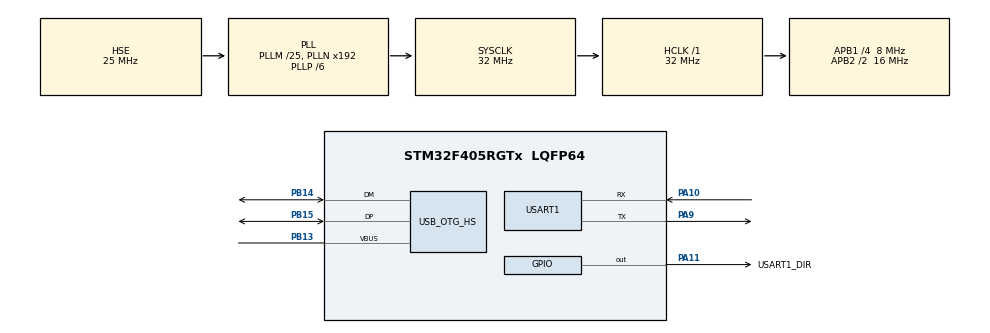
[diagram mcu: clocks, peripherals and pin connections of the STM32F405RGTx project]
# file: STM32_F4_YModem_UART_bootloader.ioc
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Mcu.Family=STM32F4
Mcu.Name=STM32F405RGTx
Mcu.Package=LQFP64
NVIC.OTG_HS_IRQn=true\:0\:0\:false\:false\:true\:false\:true
NVIC.PriorityGroup=NVIC_PRIORITYGROUP_4
PA10.Mode=Asynchronous
PA10.Signal=USART1_RX
PA11.GPIO_Label=USART1_DIR
PA11.Signal=GPIO_Output
PA13.Mode=Serial_Wire
PA13.Signal=SYS_JTMS-SWDIO
PA14.Mode=Serial_Wire
PA14.Signal=SYS_JTCK-SWCLK
PA9.Mode=Asynchronous
PA9.Signal=USART1_TX
PB13.Mode=Activate_VBUS_FS
PB13.Signal=USB_OTG_HS_VBUS
PB14.Mode=Device_Only_FS
PB14.Signal=USB_OTG_HS_DM
PB15.Mode=Device_Only_FS
PB15.Signal=USB_OTG_HS_DP
PH0-OSC_IN.Mode=HSE-External-Oscillator
PH0-OSC_IN.Signal=RCC_OSC_IN
PH1-OSC_OUT.Mode=HSE-External-Oscillator
PH1-OSC_OUT.Signal=RCC_OSC_OUT
ProjectManager.HeapSize=0x200
ProjectManager.StackSize=0x400
ProjectManager.TargetToolchain=STM32CubeIDE
RCC.48MHZClocksFreq_Value=48000000
RCC.AHBFreq_Value=32000000
RCC.APB1CLKDivider=RCC_HCLK_DIV4
RCC.APB1Freq_Value=8000000
RCC.APB1TimFreq_Value=16000000
RCC.APB2CLKDivider=RCC_HCLK_DIV2
RCC.APB2Freq_Value=16000000
RCC.APB2TimFreq_Value=32000000
RCC.CortexFreq_Value=32000000
RCC.HCLKFreq_Value=32000000
RCC.HSE_VALUE=25000000
RCC.HSI_VALUE=16000000
RCC.LSE_VALUE=32768
RCC.PLLM=25
RCC.PLLP=RCC_PLLP_DIV6
RCC.SYSCLKFreq_VALUE=32000000
RCC.SYSCLKSource=RCC_SYSCLKSOURCE_PLLCLK
RCC.VCOOutputFreq_Value=192000000
USART1.VirtualMode=VM_ASYNC
USB_DEVICE.CLASS_NAME_HS=CDC
USB_DEVICE.MANUFACTURER_STRING-CDC_HS=Micronix
USB_DEVICE.PRODUCT_STRING_CDC_HS=Micronix VD Device
USB_DEVICE.VirtualMode-CDC_HS=Cdc
USB_DEVICE.VirtualModeHS=Cdc_HS
USB_OTG_HS.VirtualMode-Device_Only_FS=Device_Only_FS
VP_USB_DEVICE_VS_USB_DEVICE_CDC_HS.Mode=CDC_HS
board=custom

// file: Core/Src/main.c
/* USER CODE BEGIN Header */
/**
  ******************************************************************************
  * @file           : main.c
  * @brief          : Main program body
  ******************************************************************************
  * @attention
  *
  * <h2><center>&copy; Copyright (c) 2025 STMicroelectronics.
  * All rights reserved.</center></h2>
  *
  * This software component is licensed by ST under BSD 3-Clause license,
  * the "License"; You may not use this file except in compliance with the
  * License. You may obtain a copy of the License at:
  *                        opensource.org/licenses/BSD-3-Clause
  *
  ******************************************************************************
  */
/* USER CODE END Header */
#include "main.h"
#ifdef USE_INTERFACE_USB
#include "usb_device.h"
#endif

/* USER CODE BEGIN Includes */
#include "cpu.h"
#include "drivers/transport/uart_transport.h"
#ifdef USE_INTERFACE_USB
#include "drivers/transport/usb_cdc_transport.h"
#endif
/* USER CODE END Includes */

UART_HandleTypeDef huart1;

void SystemClock_Config(void);
static void MX_GPIO_Init(void);
static void MX_USART1_UART_Init(void);

int main(void)
{

  /* MCU Configuration--------------------------------------------------------*/

  /* Reset of all peripherals, Initializes the Flash interface and the Systick. */
  HAL_Init();

  /* Configure the system clock */
  SystemClock_Config();

  /* Initialize all configured peripherals */
  MX_GPIO_Init();
  MX_USART1_UART_Init();
#ifdef USE_INTERFACE_USB
  MX_USB_DEVICE_Init();
#endif
  /* USER CODE BEGIN 2 */
#ifdef USE_INTERFACE_USB
  cpu(&usb_cdc_ctx);
#else
  cpu(&uart_ctx);
#endif
  /* USER CODE END 2 */

  /* Infinite loop */
  while (1)
  {

  }
}

void SystemClock_Config(void)
{
  RCC_OscInitTypeDef RCC_OscInitStruct = {0};
  RCC_ClkInitTypeDef RCC_ClkInitStruct = {0};
  uint32_t flash_latency = FLASH_LATENCY_0;

  /** Configure the main internal regulator output voltage
  */
  __HAL_RCC_PWR_CLK_ENABLE();
  __HAL_PWR_VOLTAGESCALING_CONFIG(PWR_REGULATOR_VOLTAGE_SCALE1);
  /** Initializes the RCC Oscillators according to the specified parameters
  * in the RCC_OscInitTypeDef structure.
  */
#ifdef USE_INTERFACE_USB
  RCC_OscInitStruct.OscillatorType = RCC_OSCILLATORTYPE_HSE;
  RCC_OscInitStruct.HSEState = RCC_HSE_ON;
  RCC_OscInitStruct.PLL.PLLState = RCC_PLL_ON;
  RCC_OscInitStruct.PLL.PLLSource = RCC_PLLSOURCE_HSE;
  RCC_OscInitStruct.PLL.PLLM = 25;
  RCC_OscInitStruct.PLL.PLLN = 192;
  RCC_OscInitStruct.PLL.PLLP = RCC_PLLP_DIV6;
  RCC_OscInitStruct.PLL.PLLQ = 4;
#else
  RCC_OscInitStruct.OscillatorType = RCC_OSCILLATORTYPE_HSI;
  RCC_OscInitStruct.HSIState = RCC_HSI_ON;
  RCC_OscInitStruct.HSICalibrationValue = RCC_HSICALIBRATION_DEFAULT;
  RCC_OscInitStruct.PLL.PLLState = RCC_PLL_NONE;
#endif
  if (HAL_RCC_OscConfig(&RCC_OscInitStruct) != HAL_OK)
  {
    Error_Handler();
  }
  /** Initializes the CPU, AHB and APB buses clocks
  */
  RCC_ClkInitStruct.ClockType = RCC_CLOCKTYPE_HCLK|RCC_CLOCKTYPE_SYSCLK
                              |RCC_CLOCKTYPE_PCLK1|RCC_CLOCKTYPE_PCLK2;
#ifdef USE_INTERFACE_USB
  RCC_ClkInitStruct.SYSCLKSource = RCC_SYSCLKSOURCE_PLLCLK;
#else
  RCC_ClkInitStruct.SYSCLKSource = RCC_SYSCLKSOURCE_HSI;
#endif
  RCC_ClkInitStruct.AHBCLKDivider = RCC_SYSCLK_DIV1;
#ifdef USE_INTERFACE_USB
  RCC_ClkInitStruct.APB1CLKDivider = RCC_HCLK_DIV4;
  RCC_ClkInitStruct.APB2CLKDivider = RCC_HCLK_DIV2;
  flash_latency = FLASH_LATENCY_1;
#else
  RCC_ClkInitStruct.APB1CLKDivider = RCC_HCLK_DIV1;
  RCC_ClkInitStruct.APB2CLKDivider = RCC_HCLK_DIV1;
#endif

  if (HAL_RCC_ClockConfig(&RCC_ClkInitStruct, flash_latency) != HAL_OK)
  {
    Error_Handler();
  }
}

static void MX_USART1_UART_Init(void)
{

  huart1.Instance = USART1;
  huart1.Init.BaudRate = 115200;
  huart1.Init.WordLength = UART_WORDLENGTH_8B;
  huart1.Init.StopBits = UART_STOPBITS_1;
  huart1.Init.Parity = UART_PARITY_NONE;
  huart1.Init.Mode = UART_MODE_TX_RX;
  huart1.Init.HwFlowCtl = UART_HWCONTROL_NONE;
  huart1.Init.OverSampling = UART_OVERSAMPLING_16;
  if (HAL_UART_Init(&huart1) != HAL_OK)
  {
    Error_Handler();
  }

}

static void MX_GPIO_Init(void)
{
  GPIO_InitTypeDef GPIO_InitStruct = {0};

  /* GPIO Ports Clock Enable */
#ifdef USE_INTERFACE_USB
  __HAL_RCC_GPIOH_CLK_ENABLE();
  __HAL_RCC_GPIOB_CLK_ENABLE();
#endif
  __HAL_RCC_GPIOA_CLK_ENABLE();

  /*Configure GPIO pin Output Level */
  HAL_GPIO_WritePin(USART1_DIR_GPIO_Port, USART1_DIR_Pin, GPIO_PIN_RESET);

  /*Configure GPIO pin : USART1_DIR_Pin */
  GPIO_InitStruct.Pin = USART1_DIR_Pin;
  GPIO_InitStruct.Mode = GPIO_MODE_OUTPUT_PP;
  GPIO_InitStruct.Pull = GPIO_NOPULL;
  GPIO_InitStruct.Speed = GPIO_SPEED_FREQ_LOW;
  HAL_GPIO_Init(USART1_DIR_GPIO_Port, &GPIO_InitStruct);

}

void Error_Handler(void)
{
  __disable_irq();
  while (1)
  {
  }
}

/************************ (C) COPYRIGHT STMicroelectronics *****END OF FILE****/
